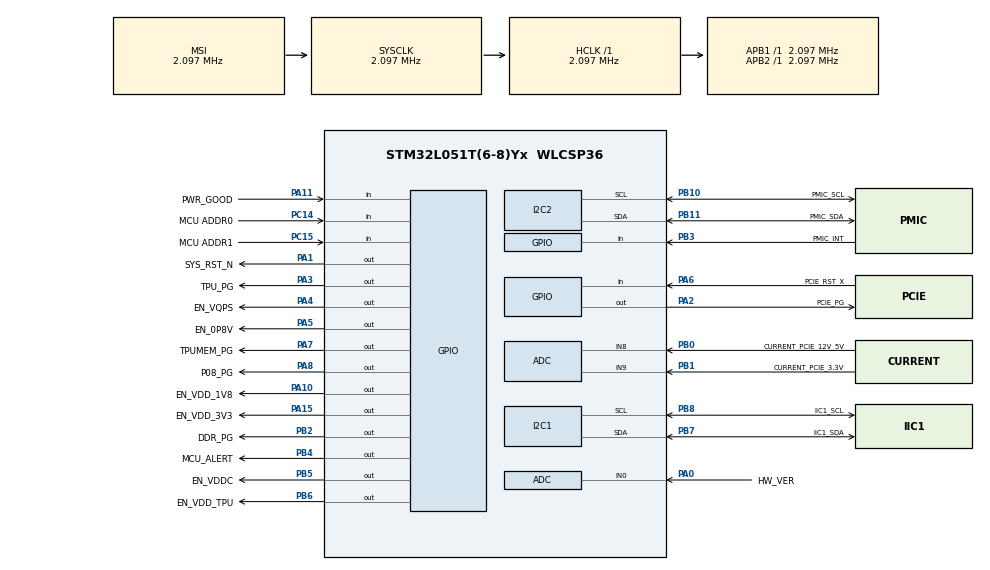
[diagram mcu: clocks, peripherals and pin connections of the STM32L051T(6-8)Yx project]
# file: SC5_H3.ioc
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Mcu.Family=STM32L0
PB10.Mode=I2C
PA10.GPIO_PuPd=GPIO_PULLDOWN
PA0.GPIO_Label=HW_VER
VP_RTC_VS_RTC_Activate.Mode=RTC_Enabled
PA6.GPIO_Label=PCIE_RST_X
PB0.GPIO_Label=CURRENT_PCIE_12V_5V
PB6.GPIO_Label=EN_VDD_TPU
PA11.GPIO_PuPd=GPIO_PULLDOWN
PB11.Signal=I2C2_SDA
PC15-OSC32_OUT.GPIO_Label=MCU ADDR1
ProjectManager.StackSize=0x400
NVIC.I2C1_IRQn=true\:1\:0\:true\:false\:true\:true\:true
ADC.DiscontinuousConvMode=ENABLE
PA15.GPIO_Label=EN_VDD_3V3
RCC.APB2TimFreq_Value=2097000
PB6.Signal=GPIO_Output
PA1.GPIO_PuPd=GPIO_NOPULL
RCC.AHBFreq_Value=2097000
PB2.Signal=GPIO_Output
PB3.GPIO_PuPd=GPIO_PULLUP
PB1.GPIO_Label=CURRENT_PCIE_3.3V
PA0.Mode=IN0
PA10.GPIO_Label=EN_VDD_1V8
PB7.Signal=I2C1_SDA
PA8.Signal=GPIO_Output
PA0.Signal=ADC_IN0
PB7.GPIO_Label=IIC1_SDA
Mcu.Package=WLCSP36
PA6.Signal=GPIO_Input
PB1.Signal=ADC_IN9
PA2.GPIO_ModeDefaultOutputPP=GPIO_MODE_OUTPUT_PP
PA2.GPIO_Label=PCIE_PG
VP_LPTIM1_VS_LPTIM_counterModeInternalClock.Mode=Counts__internal_clock_event_00
PA10.Signal=GPIO_Output
PA15.Signal=GPIO_Output
PB5.GPIO_Label=EN_VDDC
RCC.APB1TimFreq_Value=2097000
PC14-OSC32_IN.GPIO_Label=MCU ADDR0
PA4.GPIO_Label=EN_VQPS
PB4.Signal=GPIO_Output
PA3.Signal=GPIO_Output
PB3.GPIO_Label=PMIC_INT
RCC.MSI_VALUE=2097000
PB11.GPIO_Label=PMIC_SDA
PA11.GPIO_Label=PWR_GOOD
PC14-OSC32_IN.Signal=GPIO_Input
I2C1.OwnAddress2=0x68
I2C1.DualAddressMode=I2C_DUALADDRESS_ENABLE
RCC.HSI16_VALUE=16000000
PB8.GPIO_Label=IIC1_SCL
PA8.GPIO_Label=P08_PG
PB11.Mode=I2C
ProjectManager.TargetToolchain=TrueSTUDIO
PB10.GPIO_Label=PMIC_SCL
NVIC.I2C2_IRQn=true\:0\:0\:false\:false\:true\:true\:true
PB4.GPIO_PuPd=GPIO_PULLDOWN
RCC.LSE_VALUE=32768
PC15-OSC32_OUT.Signal=GPIO_Input
PA1.Signal=GPIO_Output
PB10.Signal=I2C2_SCL
PA5.Signal=GPIO_Output
PB0.Mode=IN8
board=custom
RCC.VCOOutputFreq_Value=48000000
RCC.APB2Freq_Value=2097000
I2C1.OwnAddress2Masks=I2C_OA2_MASK02
PB4.GPIO_Label=MCU_ALERT
PA1.GPIO_Label=SYS_RST_N
Mcu.Name=STM32L051T(6-8)Yx
PA2.Signal=GPIO_Output
I2C1.OwnAddress=0x17
PB3.Signal=GPIO_Input
PA4.Signal=GPIO_Output
RCC.SYSCLKFreq_VALUE=2097000
PB5.Signal=GPIO_Output
PA7.GPIO_Label=TPUMEM_PG
PA5.GPIO_Label=EN_0P8V
PB5.GPIO_PuPd=GPIO_PULLDOWN
PA11.Signal=GPIO_Input
PB7.Mode=I2C
PB2.GPIO_Label=DDR_PG
ProjectManager.HeapSize=0x200
PB1.Mode=IN9
RCC.HSI_VALUE=16000000
PB8.Mode=I2C
PB8.Signal=I2C1_SCL
RCC.APB1Freq_Value=2097000
PB0.Signal=ADC_IN8
PA3.GPIO_Label=TPU_PG
PA7.Signal=GPIO_Output
PA1.GPIO_ModeDefaultOutputPP=GPIO_MODE_OUTPUT_PP

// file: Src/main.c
/* USER CODE BEGIN Header */
/**
  ******************************************************************************
  * @file           : main.c
  * @brief          : Main program body
  ******************************************************************************
  * @attention
  *
  * <h2><center>&copy; Copyright (c) 2019 STMicroelectronics.
  * All rights reserved.</center></h2>
  *
  * This software component is licensed by ST under BSD 3-Clause license,
  * the "License"; You may not use this file except in compliance with the
  * License. You may obtain a copy of the License at:
  *                        opensource.org/licenses/BSD-3-Clause
  *
  ******************************************************************************
  */
/* USER CODE END Header */

#include "main.h"
#include "adc.h"
#include "i2c.h"
#include "lptim.h"
#include "rtc.h"
#include "gpio.h"

/* USER CODE BEGIN Includes */
#include "bm_common_func.h"
#include "mcu.h"
#include "wdt.h"
#include "upgrade.h"
/* USER CODE END Includes */

/* USER CODE BEGIN PV */
I2C_REGS i2c_regs;
/* USER CODE END PV */

void SystemClock_Config(void);

/* USER CODE BEGIN 0 */

void HAL_LPTIM_CompareMatchCallback(LPTIM_HandleTypeDef *hlptim)
{
	wdt_isr();
	mcu_tick_isr();
}

/* USER CODE END 0 */

int main(void)
{
  /* USER CODE BEGIN 1 */
  /* maybe no return */
  setup_stage();

  /* USER CODE END 1 */

  /* MCU Configuration--------------------------------------------------------*/

  /* Reset of all peripherals, Initializes the Flash interface and the Systick. */
  HAL_Init();

  /* Configure the system clock */
  SystemClock_Config();

  /* Initialize all configured peripherals */
  MX_GPIO_Init();
  MX_ADC_Init();
  MX_I2C1_Init();
  MX_I2C2_Init();
  MX_LPTIM1_Init();
  MX_RTC_Init();
  /* USER CODE BEGIN 2 */
  module_init();

  /* USER CODE END 2 */

  /* Infinite loop */
  while (1)
  {

    /* USER CODE BEGIN 3 */
	  cmd_process();

	  //get current of two channels
	  Scan_Cuerrent();
//	  Scan_Voltage();

	  //POLL PCIEE_RST STATUS FOR SYS_RST
	  poll_pcie_rst();
	  //GET_Current_Voltage();
  }
  /* USER CODE END 3 */
}

void SystemClock_Config(void)
{
  RCC_OscInitTypeDef RCC_OscInitStruct = {0};
  RCC_ClkInitTypeDef RCC_ClkInitStruct = {0};
  RCC_PeriphCLKInitTypeDef PeriphClkInit = {0};

  /** Configure the main internal regulator output voltage
  */
  __HAL_PWR_VOLTAGESCALING_CONFIG(PWR_REGULATOR_VOLTAGE_SCALE1);
  /** Initializes the CPU, AHB and APB busses clocks
  */
  RCC_OscInitStruct.OscillatorType = RCC_OSCILLATORTYPE_LSI|RCC_OSCILLATORTYPE_MSI;
  RCC_OscInitStruct.LSIState = RCC_LSI_ON;
  RCC_OscInitStruct.MSIState = RCC_MSI_ON;
  RCC_OscInitStruct.MSICalibrationValue = 0;
  RCC_OscInitStruct.MSIClockRange = RCC_MSIRANGE_5;
  RCC_OscInitStruct.PLL.PLLState = RCC_PLL_NONE;
  if (HAL_RCC_OscConfig(&RCC_OscInitStruct) != HAL_OK)
  {
    Error_Handler();
  }
  /** Initializes the CPU, AHB and APB busses clocks
  */
  RCC_ClkInitStruct.ClockType = RCC_CLOCKTYPE_HCLK|RCC_CLOCKTYPE_SYSCLK
                              |RCC_CLOCKTYPE_PCLK1|RCC_CLOCKTYPE_PCLK2;
  RCC_ClkInitStruct.SYSCLKSource = RCC_SYSCLKSOURCE_MSI;
  RCC_ClkInitStruct.AHBCLKDivider = RCC_SYSCLK_DIV1;
  RCC_ClkInitStruct.APB1CLKDivider = RCC_HCLK_DIV1;
  RCC_ClkInitStruct.APB2CLKDivider = RCC_HCLK_DIV1;

  if (HAL_RCC_ClockConfig(&RCC_ClkInitStruct, FLASH_LATENCY_0) != HAL_OK)
  {
    Error_Handler();
  }
  PeriphClkInit.PeriphClockSelection = RCC_PERIPHCLK_I2C1|RCC_PERIPHCLK_RTC
                              |RCC_PERIPHCLK_LPTIM1;
  PeriphClkInit.I2c1ClockSelection = RCC_I2C1CLKSOURCE_PCLK1;
  PeriphClkInit.RTCClockSelection = RCC_RTCCLKSOURCE_LSI;
  PeriphClkInit.LptimClockSelection = RCC_LPTIM1CLKSOURCE_PCLK;

  if (HAL_RCCEx_PeriphCLKConfig(&PeriphClkInit) != HAL_OK)
  {
    Error_Handler();
  }
}

void Error_Handler(void)
{
}

/************************ (C) COPYRIGHT STMicroelectronics *****END OF FILE****/
